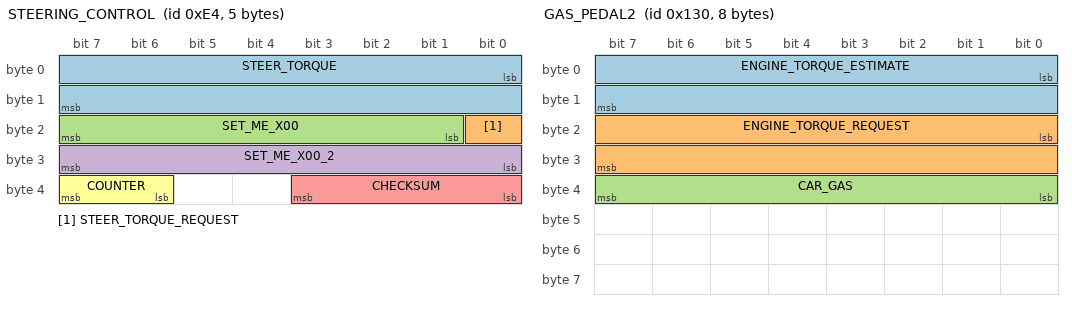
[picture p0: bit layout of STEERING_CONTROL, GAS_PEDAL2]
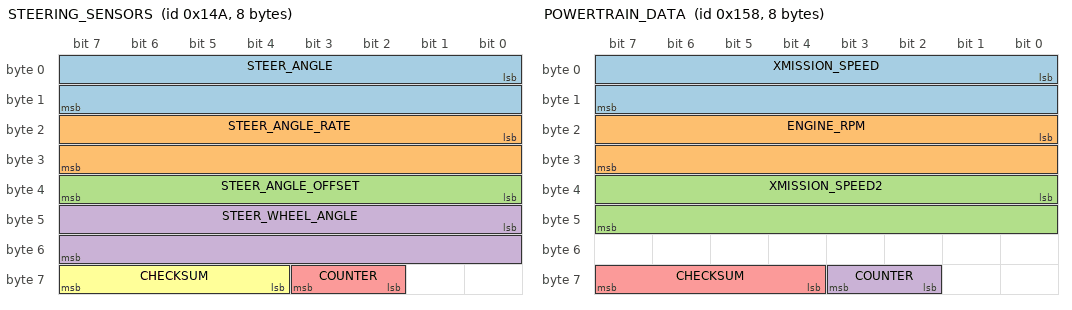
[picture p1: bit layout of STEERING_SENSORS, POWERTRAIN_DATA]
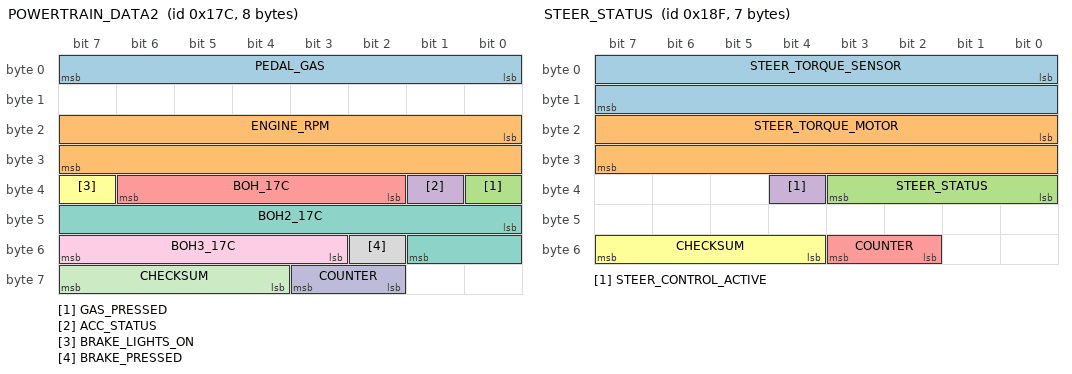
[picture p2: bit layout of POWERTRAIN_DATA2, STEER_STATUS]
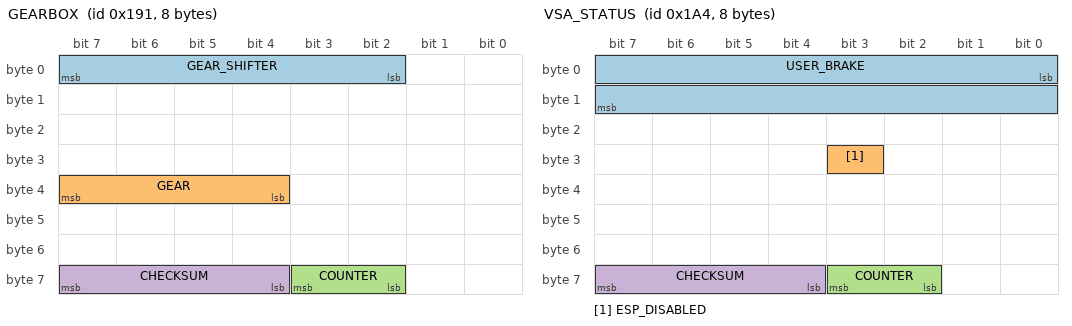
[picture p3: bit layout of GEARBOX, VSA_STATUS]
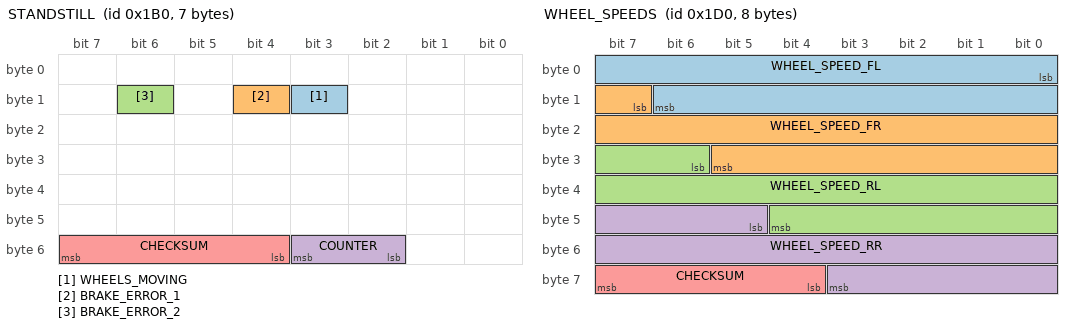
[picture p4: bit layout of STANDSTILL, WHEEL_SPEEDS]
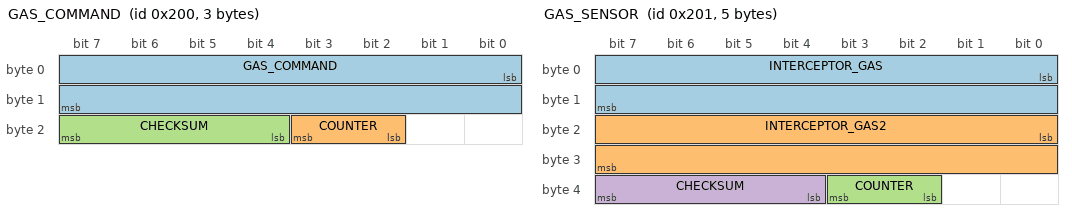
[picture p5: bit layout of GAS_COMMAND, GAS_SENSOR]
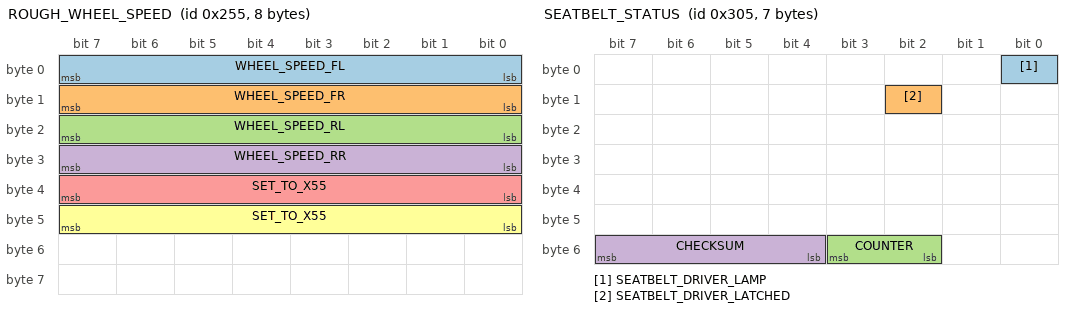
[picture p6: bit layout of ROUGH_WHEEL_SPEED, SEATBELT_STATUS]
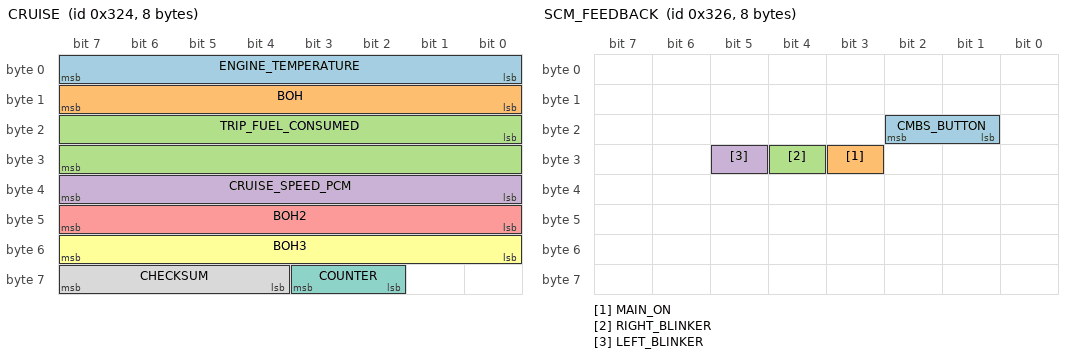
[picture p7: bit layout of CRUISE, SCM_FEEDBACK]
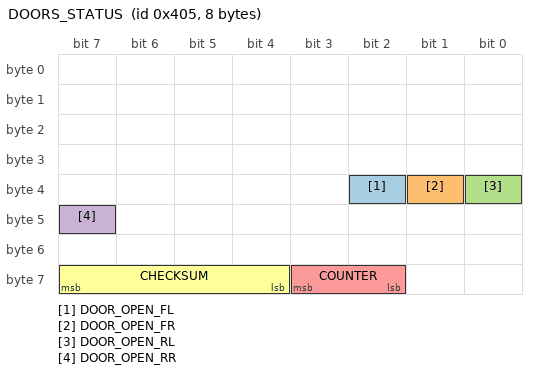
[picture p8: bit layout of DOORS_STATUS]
VERSION ""

NS_ :

BS_:

BO_ 0x039 XXX: 3 XXX

BO_ 0x94 XXX: 8 XXX
 SG_ LAT_ACCEL : 0|10@1+ (0.02,-512) [-20|20] "m/s2" Vector__XXX
 SG_ LONG_ACCEL : 31|9@1- (-0.02,0) [-20|20] "m/s2" Vector__XXX

BO_ 0x0E4 STEERING_CONTROL: 5 ADAS
 SG_ STEER_TORQUE : 0|16@1- (1,0) [-3840|3840] "" Vector__XXX
 SG_ STEER_TORQUE_REQUEST : 16|1@1+ (1,0) [0|1] "" Vector__XXX
 SG_ SET_ME_X00 : 17|7@1+ (1,0) [0|127] "" Vector__XXX
 SG_ SET_ME_X00_2 : 24|8@1+ (1,0) [0|0] "" Vector__XXX
 SG_ CHECKSUM : 32|4@1+ (1,0) [0|15] "" Vector__XXX
 SG_ COUNTER : 38|2@1+ (1,0) [0|3] "" Vector__XXX

BO_ 0x130 GAS_PEDAL2: 8 PCM
 SG_ ENGINE_TORQUE_ESTIMATE : 0|16@1- (1,0) [-1000|1000] "Nm" Vector__XXX
 SG_ ENGINE_TORQUE_REQUEST : 16|16@1- (1,0) [-1000|1000] "Nm" Vector__XXX
 SG_ CAR_GAS : 32|8@1+ (1,0) [0|255] "" Vector__XXX

BO_ 0x14A STEERING_SENSORS: 8 EPS
 SG_ STEER_ANGLE : 0|16@1- (-0.1,0) [-500|500] "deg" Vector__XXX
 SG_ STEER_ANGLE_RATE : 16|16@1- (-1,0) [-3000|3000] "deg/s" Vector__XXX
 SG_ STEER_ANGLE_OFFSET : 32|8@1- (-0.1,0) [-128|127] "deg" Vector__XXX
 SG_ STEER_WHEEL_ANGLE : 40|16@1- (-0.1,0) [-500|500] "deg" Vector__XXX
 SG_ COUNTER : 58|2@1+ (1,0) [0|3] "" Vector__XXX
 SG_ CHECKSUM : 60|4@1+ (1,0) [0|3] "" Vector__XXX

BO_ 0x158 POWERTRAIN_DATA: 8 PCM
 SG_ XMISSION_SPEED : 0|16@1+ (0.002759506,0) [0|70] "m/s" Vector__XXX
 SG_ ENGINE_RPM : 16|16@1+ (1,0) [0|15000] "rpm" Vector__XXX
 SG_ XMISSION_SPEED2 : 32|16@1+ (0.002759506,0) [0|70] "m/s" Vector__XXX
 SG_ COUNTER : 58|2@1+ (1,0) [0|3] "" Vector__XXX
 SG_ CHECKSUM : 60|4@1+ (1,0) [0|3] "" Vector__XXX

BO_ 0x17C POWERTRAIN_DATA2: 8 PCM
 SG_ PEDAL_GAS : 0|8@1+ (1,0) [0|255] "" Vector__XXX
 SG_ ENGINE_RPM : 16|16@1+ (1,0) [0|15000] "rpm" Vector__XXX
 SG_ GAS_PRESSED : 32|1@1+ (1,0) [0|1] "" Vector__XXX
 SG_ ACC_STATUS : 33|1@1+ (1,0) [0|1] "rpm" Vector__XXX
 SG_ BOH_17C : 34|5@1+ (1,0) [0|1] "rpm" Vector__XXX
 SG_ BRAKE_LIGHTS_ON : 39|1@1+ (1,0) [0|1] "rpm" Vector__XXX
 SG_ BOH2_17C : 40|10@1+ (1,0) [0|1] "rpm" Vector__XXX
 SG_ BRAKE_PRESSED : 50|1@1+ (1,0) [0|1] "" Vector__XXX
 SG_ BOH3_17C : 51|5@1+ (1,0) [0|1] "rpm" Vector__XXX
 SG_ COUNTER : 58|2@1+ (1,0) [0|3] "" Vector__XXX
 SG_ CHECKSUM : 60|4@1+ (1,0) [0|3] "" Vector__XXX

BO_ 0x18F STEER_STATUS: 7 EPS
 SG_ STEER_TORQUE_SENSOR : 0|16@1- (1,0) [-31000|31000] "tbd" Vector__XXX
 SG_ STEER_TORQUE_MOTOR : 16|16@1- (1,0) [-31000|31000] "tbd" Vector__XXX
 SG_ STEER_STATUS : 32|4@1+ (1,0) [0|15] "" Vector__XXX
 SG_ STEER_CONTROL_ACTIVE : 36|1@1+ (1,0) [0|1] "" Vector__XXX
 SG_ COUNTER : 50|2@1+ (1,0) [0|3] "" Vector__XXX
 SG_ CHECKSUM : 52|4@1+ (1,0) [0|3] "" Vector__XXX

BO_ 0x191 GEARBOX: 8 PCM
 SG_ GEAR_SHIFTER : 2|6@1+ (1,0) [0|63] "" Vector__XXX
 SG_ GEAR : 36|4@1+ (1,0) [0|15] "" Vector__XXX
 SG_ COUNTER : 58|2@1+ (1,0) [0|3] "" Vector__XXX
 SG_ CHECKSUM : 60|4@1+ (1,0) [0|3] "" Vector__XXX

BO_ 0x1A4 VSA_STATUS: 8 VSA
 SG_ USER_BRAKE : 0|16@1+ (0.015625,-103) [0|1000] "" Vector__XXX
 SG_ ESP_DISABLED : 27|1@1+ (1,0) [0|1] "" Vector__XXX
 SG_ COUNTER : 58|2@1+ (1,0) [0|3] "" Vector__XXX
 SG_ CHECKSUM : 60|4@1+ (1,0) [0|3] "" Vector__XXX

BO_ 0x1AB XXX: 3 VSA

BO_ 0x1AC XXX: 8 XXX

BO_ 0x1B0 STANDSTILL: 7 VSA
 SG_ WHEELS_MOVING : 11|1@1+ (1,0) [0|1] "" Vector__XXX
 SG_ BRAKE_ERROR_1 : 12|1@1+ (1,0) [0|1] "" Vector__XXX
 SG_ BRAKE_ERROR_2 : 14|1@1+ (1,0) [0|1] "" Vector__XXX
 SG_ COUNTER : 50|2@1+ (1,0) [0|3] "" Vector__XXX
 SG_ CHECKSUM : 52|4@1+ (1,0) [0|3] "" Vector__XXX

BO_ 0x1C2 XXX: 8 EPB
 SG_ EPB_ACTIVE : 4|1@1+ (1,0) [0|1] "" Vector__XXX
 SG_ EPB_STATE : 26|2@1+ (1,0) [0|3] "" Vector__XXX

BO_ 0x1D0 WHEEL_SPEEDS: 8 VSA
 SG_ WHEEL_SPEED_FL : 0|15@1+ (0.002759506,0) [0|70] "m/s" Vector__XXX
 SG_ WHEEL_SPEED_FR : 15|15@1+ (0.002759506,0) [0|70] "m/s" Vector__XXX
 SG_ WHEEL_SPEED_RL : 30|15@1+ (0.002759506,0) [0|70] "m/s" Vector__XXX
 SG_ WHEEL_SPEED_RR : 45|15@1+ (0.002759506,0) [0|70] "m/s" Vector__XXX
 SG_ CHECKSUM : 60|4@1+ (1,0) [0|3] "" Vector__XXX

BO_ 0x1D6 XXX: 2 VSA

BO_ 0x1DC XXX: 7 XXX

BO_ 0x1E7 XXX: 4 VSA
 SG_ BRAKE_PRESSURE1 : 0|10@1+ (0.015625,-103) [0|1000] "" Vector__XXX
 SG_ BRAKE_PRESSURE2 : 14|10@1+ (0.015625,-103) [0|1000] "" Vector__XXX

BO_ 0x1EA VEHICLE_DYNAMICS: 8 VSA
 SG_ LONG_ACCEL : 16|16@1- (0.0015384,0) [-20|20] "m/s2" Vector__XXX

BO_ 0x1ED XXX: 5 VSA

BO_ 0x1FA BRAKE_COMMAND: 8 ADAS
 SG_ COMPUTER_BRAKE : 0|10@1+ (0.003906248,0) [0|1.0] "" Vector__XXX
 SG_ ZEROS_BOH : 10|5@1+ (1,0) [0|1] "" Vector__XXX
 SG_ COMPUTER_BRAKE_REQUEST : 15|1@1+ (1,0) [0|1] "" Vector__XXX
 SG_ CRUISE_BOH2 : 16|3@1+ (1,0) [0|1] "" Vector__XXX
 SG_ CRUISE_OVERRIDE : 19|1@1+ (1,0) [0|1] "" Vector__XXX
 SG_ CRUISE_BOH3 : 20|1@1+ (1,0) [0|1] "" Vector__XXX
 SG_ CRUISE_FAULT_CMD : 21|1@1+ (1,0) [0|1] "" Vector__XXX
 SG_ CRUISE_CANCEL_CMD : 22|1@1+ (1,0) [0|1] "" Vector__XXX
 SG_ COMPUTER_BRAKE_REQUEST_2 : 23|1@1+ (1,0) [0|1] "" Vector__XXX
 SG_ SET_ME_0X80 : 24|8@1+ (1,0) [0|1] "" Vector__XXX
 SG_ BRAKE_LIGHTS : 32|1@1+ (1,0) [0|1] "" Vector__XXX
 SG_ CRUISE_STATES : 33|7@1+ (1,0) [0|1] "" Vector__XXX
 SG_ CHIME : 40|3@1+ (1,0) [0|7] "" Vector__XXX
 SG_ ZEROS_BOH6 : 43|1@1+ (1,0) [0|1] "" Vector__XXX
 SG_ FCW : 44|1@1+ (1,0) [0|3] "" Vector__XXX
 SG_ ZEROS_BOH3 : 45|2@1+ (1,0) [0|0] "" Vector__XXX
 SG_ FCW2 : 47|1@1+ (1,0) [0|0] "" Vector__XXX
 SG_ ZEROS_BOH4 : 48|8@1+ (1,0) [0|0] "" Vector__XXX
 SG_ COUNTER : 58|2@1+ (1,0) [0|3] "" Vector__XXX
 SG_ CHECKSUM : 60|4@1+ (1,0) [0|3] "" Vector__XXX

BO_ 0x200 GAS_COMMAND: 3 ADAS
 SG_ GAS_COMMAND : 0|16@1+ (0.253984064,-328) [0|1] "" Vector__XXX
 SG_ COUNTER : 18|2@1+ (1,0) [0|3] "" Vector__XXX
 SG_ CHECKSUM : 20|4@1+ (1,0) [0|3] "" Vector__XXX

BO_ 0x201 GAS_SENSOR: 5 ADAS
 SG_ INTERCEPTOR_GAS : 0|16@1+ (0.253984064,-328) [0|1] "" Vector__XXX
 SG_ INTERCEPTOR_GAS2 : 16|16@1+ (0.126992032,-656) [0|1] "" Vector__XXX
 SG_ COUNTER : 34|2@1+ (1,0) [0|3] "" Vector__XXX
 SG_ CHECKSUM : 36|4@1+ (1,0) [0|3] "" Vector__XXX

BO_ 0x221 XXX: 6 XXX

BO_ 0x255 ROUGH_WHEEL_SPEED: 8 VSA
 SG_ WHEEL_SPEED_FL : 0|8@1+ (1,0) [0|255] "mph" Vector__XXX
 SG_ WHEEL_SPEED_FR : 8|8@1+ (1,0) [0|255] "mph" Vector__XXX
 SG_ WHEEL_SPEED_RL : 16|8@1+ (1,0) [0|255] "mph" Vector__XXX
 SG_ WHEEL_SPEED_RR : 24|8@1+ (1,0) [0|255] "mph" Vector__XXX
 SG_ SET_TO_X55 : 32|8@1+ (1,0) [0|255] "" Vector__XXX
 SG_ SET_TO_X55 : 40|8@1+ (1,0) [0|255] "" Vector__XXX

BO_ 0x296 CRUISE_BUTTONS: 4 SCM
 SG_ CRUISE_BUTTONS : 0|3@1+ (1,0) [0|7] "" Vector__XXX
 SG_ CRUISE_SETTING : 4|2@1+ (1,0) [0|3] "" Vector__XXX

BO_ 0x305 SEATBELT_STATUS: 7 BDY
 SG_ SEATBELT_DRIVER_LAMP : 0|1@1+ (1,0) [0|1] "" Vector__XXX
 SG_ SEATBELT_DRIVER_LATCHED : 10|1@1+ (1,0) [0|1] "" Vector__XXX
 SG_ COUNTER : 50|2@1+ (1,0) [0|3] "" Vector__XXX
 SG_ CHECKSUM : 52|4@1+ (1,0) [0|3] "" Vector__XXX

BO_ 0x309 XXX: 8 XXX

BO_ 0x30C ACC_HUD: 8 ADAS
 SG_ PCM_SPEED : 0|16@1+ (0.002763889,0) [0|100] "m/s" Vector__XXX
 SG_ PCM_GAS : 16|7@1+ (1,0) [0|127] "" Vector__XXX
 SG_ ZEROS_BOH : 23|1@1+ (1,0) [0|255] "" Vector__XXX
 SG_ CRUISE_SPEED : 24|8@1+ (1,0) [0|255] "" Vector__XXX
 SG_ DTC_MODE : 32|1@1+ (1,0) [0|1] "" Vector__XXX
 SG_ BOH : 33|1@1+ (1,0) [0|1] "" Vector__XXX
 SG_ ACC_PROBLEM : 34|1@1+ (1,0) [0|1] "" Vector__XXX
 SG_ FCM_OFF : 35|1@1+ (1,0) [0|1] "" Vector__XXX
 SG_ BOH_2 : 36|1@1+ (1,0) [0|1] "" Vector__XXX
 SG_ FCM_PROBLEM : 37|1@1+ (1,0) [0|1] "" Vector__XXX
 SG_ RADAR_OBSTRUCTED : 38|1@1+ (1,0) [0|1] "" Vector__XXX
 SG_ ENABLE_MINI_CAR : 39|1@1+ (1,0) [0|1] "" Vector__XXX
 SG_ HUD_DISTANCE : 40|2@1+ (1,0) [0|3] "" Vector__XXX
 SG_ HUD_LEAD : 42|2@1+ (1,0) [0|3] "" Vector__XXX
 SG_ BOH_3 : 44|1@1+ (1,0) [0|3] "" Vector__XXX
 SG_ BOH_4 : 45|1@1+ (1,0) [0|3] "" Vector__XXX
 SG_ BOH_5 : 46|1@1+ (1,0) [0|3] "" Vector__XXX
 SG_ CRUISE_CONTROL_LABEL : 47|1@1+ (1,0) [0|3] "" Vector__XXX
 SG_ COUNTER : 58|2@1+ (1,0) [0|3] "" Vector__XXX
 SG_ CHECKSUM : 60|4@1+ (1,0) [0|3] "" Vector__XXX

BO_ 0x31B XXX: 8 XXX

BO_ 0x320 XXX: 8 XXX

BO_ 0x324 CRUISE: 8 PCM
 SG_ ENGINE_TEMPERATURE : 0|8@1+ (1,0) [0|255] "" Vector__XXX
 SG_ BOH : 8|8@1+ (1,0) [0|255] "" Vector__XXX
 SG_ TRIP_FUEL_CONSUMED : 16|16@1+ (1,0) [0|255] "" Vector__XXX
 SG_ CRUISE_SPEED_PCM : 32|8@1+ (1,0) [0|255] "" Vector__XXX
 SG_ BOH2 : 40|8@1- (1,0) [0|255] "" Vector__XXX
 SG_ BOH3 : 48|8@1+ (1,0) [0|255] "" Vector__XXX
 SG_ COUNTER : 58|2@1+ (1,0) [0|3] "" Vector__XXX
 SG_ CHECKSUM : 60|4@1+ (1,0) [0|3] "" Vector__XXX

BO_ 0x326 SCM_FEEDBACK: 8 SCM
 SG_ CMBS_BUTTON : 17|2@1+ (1,0) [0|3] "" Vector__XXX
 SG_ MAIN_ON : 27|1@1+ (1,0) [0|1] "" Vector__XXX
 SG_ RIGHT_BLINKER : 28|1@1+ (1,0) [0|1] "" Vector__XXX
 SG_ LEFT_BLINKER : 29|1@1+ (1,0) [0|1] "" Vector__XXX

BO_ 0x328 XXX: 8 XXX

BO_ 0x33D LKAS_HUD_2: 5 ADAS
 SG_ CAM_TEMP_HIGH : 0|1@1+ (1,0) [0|255] "" Vector__XXX
 SG_ BOH : 1|7@1+ (1,0) [0|127] "" Vector__XXX
 SG_ DASHED_LANES : 9|1@1+ (1,0) [0|1] "" Vector__XXX
 SG_ DTC : 10|1@1+ (1,0) [0|1] "" Vector__XXX
 SG_ LKAS_PROBLEM : 11|1@1+ (1,0) [0|1] "" Vector__XXX
 SG_ LKAS_OFF : 12|1@1+ (1,0) [0|1] "" Vector__XXX
 SG_ SOLID_LANES : 13|1@1+ (1,0) [0|1] "" Vector__XXX
 SG_ LDW_RIGHT : 14|1@1+ (1,0) [0|1] "" Vector__XXX
 SG_ STEERING_REQUIRED : 15|1@1+ (1,0) [0|1] "" Vector__XXX
 SG_ BOH : 16|2@1+ (1,0) [0|4] "" Vector__XXX
 SG_ LDW_PROBLEM : 18|1@1+ (1,0) [0|1] "" Vector__XXX
 SG_ BEEP : 22|2@1+ (1,0) [0|1] "" Vector__XXX
 SG_ LDW_ON : 27|1@1+ (1,0) [0|1] "" Vector__XXX
 SG_ LDW_OFF : 28|1@1+ (1,0) [0|1] "" Vector__XXX
 SG_ CLEAN_WINDSHIELD : 29|1@1+ (1,0) [0|1] "" Vector__XXX
 SG_ SET_ME_X48 : 24|8@1+ (1,0) [0|255] "" Vector__XXX
 SG_ COUNTER : 34|2@1+ (1,0) [0|3] "" Vector__XXX
 SG_ CHECKSUM : 36|4@1+ (1,0) [0|3] "" Vector__XXX

BO_ 0x35E XXX: 8 ADAS
 SG_ UI_ALERTS : 0|56@1+ (1,0) [0|127] "" Vector__XXX

BO_ 0x374 XXX: 8 XXX
BO_ 0x37B XXX: 8 XXX
BO_ 0x37C XXX: 8 XXX

BO_ 0x39F XXX: 8 ADAS
 SG_ ZEROS_BOH : 0|17@1+ (1,0) [0|127] "" Vector__XXX
 SG_ APPLY_BRAKES_FOR_CANC : 16|1@1+ (1,0) [0|15] "" Vector__XXX
 SG_ ZEROS_BOH2 : 17|1@1+ (1,0) [0|1] "" Vector__XXX
 SG_ RESUME_INSTRUCTION : 18|1@1+ (1,0) [0|15] "" Vector__XXX
 SG_ ACC_ALERTS : 19|5@1+ (1,0) [0|15] "" Vector__XXX
 SG_ ZEROS_BOH2 : 24|8@1+ (1,0) [0|127] "" Vector__XXX
 SG_ LEAD_SPEED : 32|9@1+ (1,0) [0|127] "" Vector__XXX
 SG_ LEAD_STATE : 41|3@1+ (1,0) [0|127] "" Vector__XXX
 SG_ LEAD_DISTANCE : 44|5@1+ (1,0) [0|31] "" Vector__XXX
 SG_ ZEROS_BOH3 : 49|7@1+ (1,0) [0|127] "" Vector__XXX

BO_ 0x3A1 XXX: 8 XXX
BO_ 0x3D9 XXX: 3 XXX
BO_ 0x400 XXX: 5 XXX
BO_ 0x403 XXX: 5 XXX

BO_ 0x405 DOORS_STATUS: 8 BDY
 SG_ DOOR_OPEN_FL : 34|1@1+ (1,0) [0|1] "" Vector__XXX
 SG_ DOOR_OPEN_FR : 33|1@1+ (1,0) [0|1] "" Vector__XXX
 SG_ DOOR_OPEN_RL : 32|1@1+ (1,0) [0|1] "" Vector__XXX
 SG_ DOOR_OPEN_RR : 47|1@1+ (1,0) [0|1] "" Vector__XXX
 SG_ COUNTER : 58|2@1+ (1,0) [0|3] "" Vector__XXX
 SG_ CHECKSUM : 60|4@1+ (1,0) [0|3] "" Vector__XXX

BO_ 0x40C XXX: 8 XXX
BO_ 0x40F XXX: 8 XXX
BO_ 0x454 XXX: 8 XXX
BO_ 0x516 XXX: 8 XXX
BO_ 0x52A XXX: 5 XXX
BO_ 0x551 XXX: 5 XXX
BO_ 0x555 XXX: 5 XXX
BO_ 0x590 XXX: 5 XXX
BO_ 0x640 XXX: 5 XXX
BO_ 0x641 XXX: 8 XXX
BO_ 0x661 XXX: 8 XXX

VAL_ 0x296 CRUISE_BUTTONS 7 "tbd" 6 "tbd" 5 "tbd" 4 "accel_res" 3 "decel_set" 2 "cancel" 1 "main" 0 "none";
VAL_ 0x296 CRUISE_SETTING 3 "distance_adj" 2 "tbd" 1 "lkas_button" 0 "none";
VAL_ 0x33D HUD_LEAD 3 "acc_off" 2 "solid_car" 1 "dashed_car" 0 "no_car";
VAL_ 0x1A6 LIGHTS_SETTING 3 "high_beam" 2 "low_beam" 1 "position" 0 "no_lights";
VAL_ 0x18F STEER_STATUS 5 "fault" 4 "no_torque_alert_2" 2 "no_torque_alert_1" 0 "normal";
VAL_ 0x191 GEAR_SHIFTER 32 "L" 16 "S" 8 "D" 4 "N" 2 "R" 1 "P";
VAL_ 0x33D BEEP 3 "single_beep" 2 "triple_beep" 1 "repeated_beep" 0 "no_beep";
VAL_ 0x1FA CHIME 4 "double_chime" 3 "single_chime" 2 "continuous_chime" 1 "repeating_chime" 0 "no_chime";
VAL_ 0x1C2 EPB_STATE 3 "engaged" 2 "disengaging" 1 "engaging" 0 "disengaged";
VAL_ 0x326 CMBS_BUTTON 3 "pressed" 0 "released";
VAL_ 0x39F ACC_ALERTS 29 "esp_active_acc_canceled" 10 "b_pedal_applied" 9 "speed_too_low"  8 "speed_too_high" 7 "p_brake_applied" 6 "gear_no_d" 5 "seatbelt" 4 "too_steep_downhill" 3 "too_steep_uphill" 2 "too_close" 1 "no_vehicle_ahead";
VAL_ 0x30C CRUISE_SPEED 255 "no_speed" 252 "stopped";

CM_ SG_ 0x1A3 GEAR "10 = reverse, 11 = transition";
CM_ SG_ 0x324 CRUISE_SPEED_PCM "255 = no speed";
CM_ SG_ 0x30C CRUISE_SPEED "255 = no speed";
CM_ SG_ 0x1EA LONG_ACCEL "wheel speed derivative, noisy and zero snapping";
CM_ SG_ 0x33D BEEP "beeps are pleasant, chimes are for warnngs etc...";
